# FM33LG0XX register map
File version: 1.0
CPU: SC000 r1p0, little endian, no MPU, no FPU, 3 interrupt priority bits
Registers are 32-bit, read-write, reset 0x0 unless marked. A register's access mark holds for its fields unless they carry their own. Offsets are from the block's base; lines under a group give offsets from that group; [hi:lo] are bit positions; {n}, {i} and the like mark numbered series; 'fields as' and 'values as' point back to an identical list; <NAME> marks a mode.

## Memory map
0x40000000 DBG size 0xC — DBG module information
0x40000400 DMA size 0x4C — DMA module information
0x40000C00 GPIOA size 0x30 — GPIOA module information
0x40000C40 GPIOB size 0x30
0x40000C80 GPIOC size 0x30
0x40000CC0 GPIOD size 0x30
0x40000D00 GPIOE size 0x30
0x40000DC0 GPIO size 0x144 — GPIO module information
0x40001000 FLS size 0x24 — FLS module information
0x40002000 PMU size 0x4C — PMU module information
0x40002400 CMU size 0x64 — CMU module information
0x40002800 RMU size 0x24 — RMU module information
0x40010000 CRC size 0x20 — CRC module information
0x40010400 SPI0 size 0x1C — SPI0 module information
0x40010800 SPI1 size 0x1C
0x40010C00 LCD size 0x5C — LCD module information
0x40011000 RTCA size 0x80 — RTCA module information
0x40011400 IWDT size 0x18 — IWDT module information
0x40011800 WWDT size 0x18 — WWDT module information
0x40011C00 U7816 size 0x24 — U7816 module information
0x40012000 UART0 size 0x1C — UART0 module information
0x40012400 I2C size 0x3C — I2C module information
0x40012800 SVD size 0x14 — SVD module information
0x40013000 ATIM size 0x64 — ATIM module information
0x40013400 LPTIM32 size 0x30 — LPTIM32 module information
0x40013800 AES size 0x54 — AES module information
0x40013C00 RNG size 0x20 — RNG module information
0x40014000 LPUART0 size 0x1C — LPUART0 module information
0x40014400 LPUART1 size 0x1C
0x40014800 SPI2 size 0x1C
0x40014C00 GPTIM0 size 0x64 — GPTIM0 module information
0x40015000 LPUART2 size 0x1C
0x40015400 COMP size 0x18 — COMP module information
0x40015C00 ADC size 0x30 — ADC module information
0x40016000 BSTIM32 size 0x30 — BSTIM32 module information
0x40016400 GPTIM1 size 0x64
0x40016800 UART1 size 0x1C
0x40016C00 PGL size 0x2C — PGL module information
0x40017000 UART3 size 0x1C — UART3 module information
0x40017400 UART4 size 0x1C
0x40017800 UART5 size 0x1C
0x40017C00 UART size 0x1C — UART module information
0x40018000 GPTIM2 size 0x64
0x40018800 LPTIM16 size 0x28 — LPTIM16 module information
0x40018C00 BSTIM size 0x30 — BSTIM module information
0x40019400 CAN size 0x84 — CAN module information
0x40019800 DAC size 0x20 — DAC module information
0x40019C00 DIVAS size 0x1C — DIVAS module information
0x4001A000 OPA1 size 0xC — OPA1 module information
0x4001A400 VREF size 0x14 — VREF module information
0x4001E000 CDIF size 0x8 — CDIF module information
0x4001F000 VAO size 0xC1C — VAO module information
0x4001F000 RTCB size 0x80 — RTCB module information

## Interrupts
0 WDT (IWDT, WWDT) — WDT interrupt
1 SVD — SVD interrupt
2 RTC (RTCA, RTCB) — RTC interrupt
3 FLASH (FLS) — FLASH interrupt
4 FDET (CMU) — FDET interrupt
5 ADC — ADC interrupt
6 DAC — DAC interrupt
7 SPI0 — SPI0 interrupt
8 SPI1 — SPI1 interrupt
9 SPI2 — SPI2 interrupt
10 UART0 — UART0 interrupt
11 UART1 — UART1 interrupt
12 UART3 — UART3 interrupt
13 UART4 — UART4 interrupt
14 UART5 — UART5 interrupt
15 U7816 — U7816 interrupt
16 LPUARTX (LPUART{n} (n=0..2)) — LPUARTX interrupt
17 I2C — I2C interrupt
18 CCL (CMU) — CCL interrupt
19 AES — AES interrupt
20 LPTIM (LPTIM32, LPTIM16) — LPTIM interrupt
21 DMA — DMA interrupt
22 WKUPX (GPIO) — WKUPX interrupt
23 LUT (ATIM, GPTIM{n} (n=0..2), ADC) — LUT interrupt
24 BSTIM (BSTIM32) — BSTIM interrupt
25 COMPX (COMP) — COMPX interrupt
26 GPTIM0_1 (GPTIM0, GPTIM1) — GPTIM0_1 interrupt
27 GPTIM2 — GPTIM2 interrupt
28 ATIM — ATIM interrupt
29 VREF — VREF interrupt
30 EXTI (GPIO) — EXTI interrupt
31 CAN — CAN interrupt

## FLS — FLS module information
Base 0x40001000
0x00 RDCR — Flash Read Control Register
  [1:0] WAIT — WAIT field description
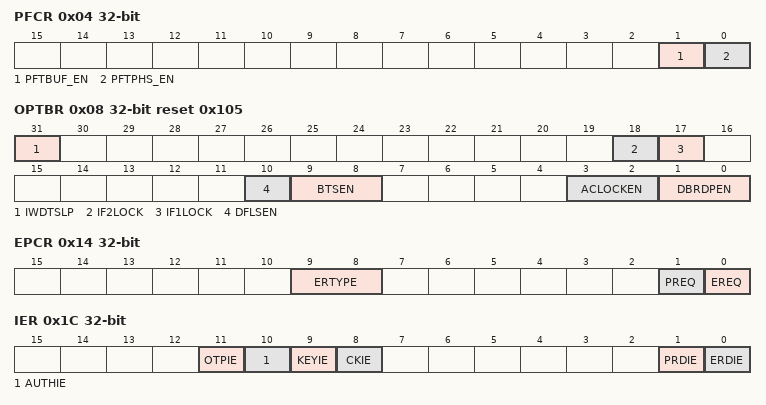
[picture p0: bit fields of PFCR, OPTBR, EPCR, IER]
0x04 PFCR — Flash Prefetch Control Register
  [1] PFTBUF_EN — PFTBUF_EN field description
  [0] PFTPHS_EN — PFTPHS_EN field description
0x08 OPTBR ro reset 0x105 — Flash Option Bytes Register
  [31] IWDTSLP — IWDTSLP field description
  [18] IF2LOCK — IF2LOCK field description
  [17] IF1LOCK — IF1LOCK field description
  [10] DFLSEN — DFLSEN field description
  [9:8] BTSEN — BTSEN field description
  [3:2] ACLOCKEN — ACLOCKEN field description
  [1:0] DBRDPEN — DBRDPEN field description
0x0C ACLOCK1 reset 0xFFFFFFFF — Flash Application Code Lock Register1
  [31:0] LOCK1 — LOCK1 field description
0x10 ACLOCK2 reset 0xFFFFFFFF — Flash Application Code Lock Register2
  [31:0] LOCK2 — LOCK2 field description
0x14 EPCR — Flash Erase/Program Control Register
  [9:8] ERTYPE — ERTYPE field description
  [1] PREQ — PREQ field description
  [0] EREQ — EREQ field description
0x18 KEY wo — Flash Key Register
  [31:0] KEY — KEY field description
0x1C IER — Flash Interrupt Enable Register
  [11] OTPIE — OTPIE field description
  [10] AUTHIE — AUTHIE field description
  [9] KEYIE — KEYIE field description
  [8] CKIE — CKIE field description
  [1] PRDIE — PRDIE field description
  [0] ERDIE — ERDIE field description
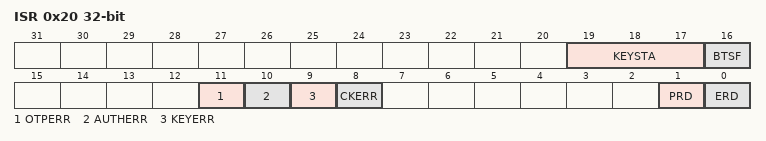
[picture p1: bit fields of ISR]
0x20 ISR access per field — Flash Interrupt Status Register
  [19:17] KEYSTA ro — KEYSTA field description
  [16] BTSF ro — BTSF field description
  [11] OTPERR rw — OTPERR field description
  [10] AUTHERR rw — AUTHERR field description
  [9] KEYERR rw — KEYERR field description
  [8] CKERR rw — CKERR field description
  [1] PRD rw — PRD field description
  [0] ERD rw — ERD field description
